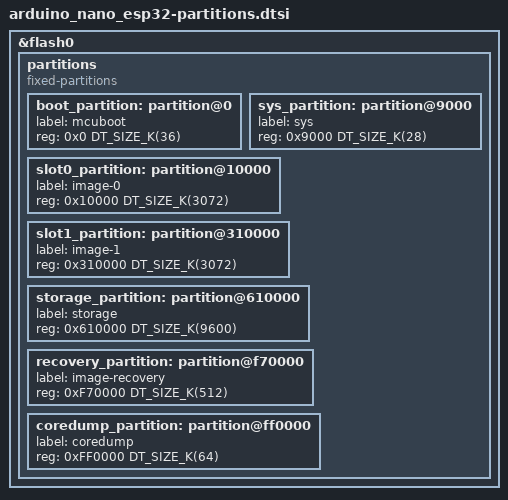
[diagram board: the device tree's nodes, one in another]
/*
 * Copyright (c) 2025 Arduino SA
 *
 * SPDX-License-Identifier: Apache-2.0
 */

&flash0 {
	partitions {
		compatible = "fixed-partitions";
		#address-cells = <1>;
		#size-cells = <1>;

		boot_partition: partition@0 {
			label = "mcuboot";
			reg = <0x0 DT_SIZE_K(36)>;
		};

		sys_partition: partition@9000 {
			label = "sys";
			reg = <0x9000 DT_SIZE_K(28)>;
		};

		slot0_partition: partition@10000 {
			label = "image-0";
			reg = <0x10000 DT_SIZE_K(3072)>;
		};

		slot1_partition: partition@310000 {
			label = "image-1";
			reg = <0x310000 DT_SIZE_K(3072)>;
		};

		storage_partition: partition@610000 {
			label = "storage";
			reg = <0x610000 DT_SIZE_K(9600)>;
		};

		recovery_partition: partition@f70000 {
			label = "image-recovery";
			reg = <0xF70000 DT_SIZE_K(512)>;
		};

		coredump_partition: partition@ff0000 {
			label = "coredump";
			reg = <0xFF0000 DT_SIZE_K(64)>;
		};
	};
};
